# MSS_MCRC register map
Vendor: Texas Instruments
Peripheral module from a debugger description file (folder awr2x44p).
Registers are 32-bit, read-only, no defined reset value unless marked. A register's access mark holds for its fields unless they carry their own. Offsets are as the file gives them; lines under a group give offsets from that group; [hi:lo] are bit positions; {n}, {i} and the like mark numbered series; 'fields as' and 'values as' point back to an identical list; <NAME> marks a mode.

## MSS_MCRC
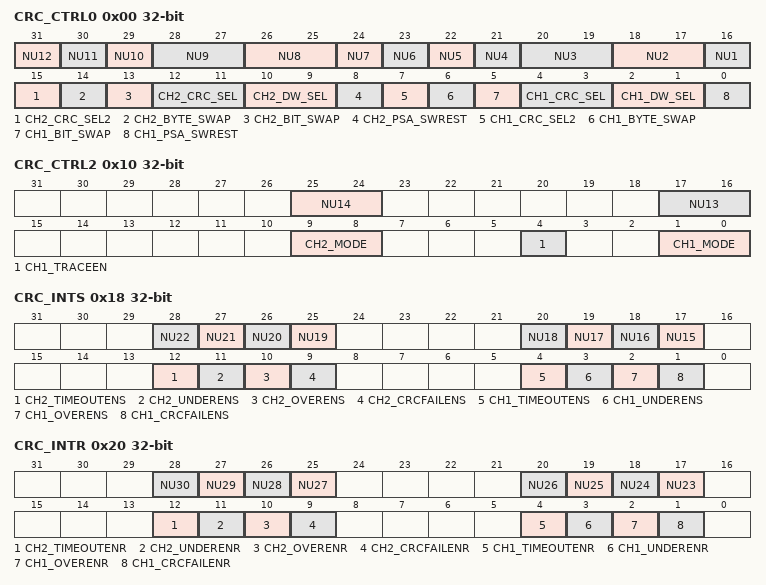
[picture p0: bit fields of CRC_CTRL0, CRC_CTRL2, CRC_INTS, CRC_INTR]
0x00 CRC_CTRL0 access per field — Contains sw reset control bit to reset PSA
  [31] NU12 ro — Reserved
  [30] NU11 ro — Reserved
  [29] NU10 ro — Reserved
  [28:27] NU9 ro — Reserved
  [26:25] NU8 ro — Reserved
  [n+17] NU{n} ro (n=4..7) — Reserved
  [20:19] NU3 ro — Reserved
  [18:17] NU2 ro — Reserved
  [16] NU1 ro — Reserved
  [15] CH2_CRC_SEL2 rw — Refer "CH2_DW_SEL" field description
  [14] CH2_BYTE_SWAP rw — BYTE SWAP Enable across Data Size 0 – Byte Swap Disabled 1 – Byte Swap enabled.
  [13] CH2_BIT_SWAP rw — msb/lsb SWAPPING 0 – msb (most significant bit First) 1 – lsb (least significant bit First)
  [12:11] CH2_CRC_SEL rw — CRC type select. {CH2_CRC_SEL2,CH2_CRC_SEL[1:0]} 000 – CRC-64 001 - CRC-16 010 – CRC-32 100 - VDA CAN, SAE-J1850 CRC-8 101 - H2F, Autosar 4.0 110 - CASTAGNOLI, iSCSI 011 - CRC64-ECMA 111 - E2E Profile 4
  [10:9] CH2_DW_SEL rw — CRC Data Size select. 000 – 64 bit Data Size 001 - 16 bit Data Size 010 – 32 Bit Data Size
  [8] CH2_PSA_SWREST rw — Channel 2 PSA Software Reset. When set, the PSA Signature Register is reset to all zero. Software reset does not reset software reset bit itself. Therefore, CPU is required to clear this bit by writing a ‘0’. 0 = PSA Signature Register not reset 1 = PSA Signature Register reset
  [7] CH1_CRC_SEL2 rw — Refer "CH1_DW_SEL" field description
  [6] CH1_BYTE_SWAP rw — BYTE SWAP Enable across Data Size 0 – Byte Swap Disabled 1 – Byte Swap enabled.
  [5] CH1_BIT_SWAP rw — msb/lsb SWAPPING 0 – msb (most significant bit First) 1 – lsb (least significant bit First)
  [4:3] CH1_CRC_SEL rw — CRC type select. {CH1_CRC_SEL2,CH1_CRC_SEL[1:0]} 000 – CRC-64 001 - CRC-16 010 – CRC-32 100 - VDA CAN, SAE-J1850 CRC-8 101 - H2F, Autosar 4.0 110 - CASTAGNOLI, iSCSI 011 - CRC64-ECMA 111 - E2E Profile 4
  [2:1] CH1_DW_SEL rw — CRC Data Size select. 000 – 64 bit Data Size 001 - 16 bit Data Size 010 – 32 Bit Data Size
  [0] CH1_PSA_SWREST rw — Channel 1 PSA Software Reset. When set, the PSA Signature Register is reset to all zero. Software reset does not reset software reset bit itself. Therefore, CPU is required to clear this bit by writing a ‘0’. 0 = PSA Signature Register not reset 1 = PSA Signature Register reset
0x08 CRC_CTRL1 access per field — Contains power down control bit
  [0] PWDN rw — Power Down. When set, MCRC moduleMCRC Module is put in power down mode. 0 = MCRC is not in power down mode 1 = MCRC is in power down mode
0x10 CRC_CTRL2 access per field — Contains channel mode, data trace enable control bits
  [25:24] NU14 ro — Reserved
  [17:16] NU13 ro — Reserved
  [9:8] CH2_MODE rw — Channel 2 Mode: 0 0 = Data Capture mode. In this mode, the PSA Signature Register does not compress data when it is written. Any data written to PSA Signature Register is simply captured by PSA Signature Register without any compression. This mode can be used to plant seed value into the PSA register 0 1 = AUTO mode 1 0 = reserved 1 1 = Full-CPU mode
  [4] CH1_TRACEEN rw — Channel 1 Data Trace Enable. When set, the channel is put into data trace mode. The channel snoops on the CPU VBUSM, ITCM, DTCM buses for any read transaction. Any read data on these buses is compressed by the PSA Signature Register. When suspend is on, the PSA Signature Register does not compress any read data on these buses. 0 = Data Trace disable 1 = Data Trace enable
  [1:0] CH1_MODE rw — Channel 1 Mode: 0 0 = Data Capture mode. In this mode, the PSA Signature Register does not compress data when it is written. Any data written to PSA Signature Register is simply captured by PSA Signature Register without any compression. This mode can be used to plant seed value into the PSA register 0 1 = AUTO mode 1 0 = reserved 1 1 = Full-CPU mode
0x18 CRC_INTS access per field — Write one to a bit to enable a interrupt
  [n+6] NU{n} ro (n=19..22) — Reserved
  [n+2] NU{n} ro (n=15..18) — Reserved
  [12] CH2_TIMEOUTENS rw — Channel 2 Timeout Interrupt Enable Bit. Writing a one to this bit enable the timeout interrupt. Writing a zero has no effect. Reading from this bit gives the status (interrupt enable/disable). User and privileged mode read: 0 = Timeout Interrupt disable 1 = Timeout Interrupt enable User and privileged mode write: 0 = Has no effect 1 = Timeout Interrupt enable
  [11] CH2_UNDERENS rw — Channel 2 Underrun Interrupt Enable Bit. Writing a one to this bit enable the underrun interrupt. Writing a zero has no effect. Reading from this bit gives the status (interrupt enable/disable). User and privileged mode read: 0 = Underrun Interrupt disable 1 = Underrun Interrupt enable User and privileged mode write: 0 = Has no effect 1 = Underrun Interrupt enable
  [10] CH2_OVERENS rw — Channel 2 Overrun Interrupt Enable Bit. Writing a one to this bit enable the overrun interrupt. Writing a zero has no effect. Reading from this bit gives the status (interrupt enable/disable). User and privileged mode read: 0 = Overrun Interrupt disable 1 = Overrun Interrupt enable User and privileged mode write: 0 = Has no effect 1 = Overrun Interrupt enable
  [9] CH2_CRCFAILENS rw — Channel 2 CRC Fail Interrupt Enable Bit. Writing a one to this bit enable the CRC fail interrupt. Writing a zero has no effect. Reading from this bit gives the status (interrupt enable/disable). User and privileged mode read: 0 = CRC Fail Interrupt disable 1 = CRC Fail Interrupt enable User and privileged mode write: 0 = Has no effect 1 = CRC Fail Interrupt enable
  [4] CH1_TIMEOUTENS rw — Channel 1 Timeout Interrupt Enable Bit. Writing a one to this bit enable the timeout interrupt. Writing a zero has no effect. Reading from this bit gives the status (interrupt enable/disable). User and privileged mode read: 0 = Timeout Interrupt disable 1 = Timeout Interrupt enable User and privileged mode write: 0 = Has no effect 1 = Timeout Interrupt enable
  [3] CH1_UNDERENS rw — Channel 1 Underrun Interrupt Enable Bit. Writing a one to this bit enable the underrun interrupt. Writing a zero has no effect. Reading from this bit gives the status (interrupt enable/disable). User and privileged mode read: 0 = Underrun Interrupt disable 1 = Underrun Interrupt enable User and privileged mode write: 0 = Has no effect 1 = Underrun Interrupt enable
  [2] CH1_OVERENS rw — Channel 1 Overrun Interrupt Enable Bit. Writing a one to this bit enable the overrun interrupt. Writing a zero has no effect. Reading from this bit gives the status (interrupt enable/disable). User and privileged mode read: 0 = Overrun Interrupt disable 1 = Overrun Interrupt enable User and privileged mode write: 0 = Has no effect 1 = Overrun Interrupt enable
  [1] CH1_CRCFAILENS rw — Channel 1 CRC Fail Interrupt Enable Bit. Writing a one to this bit enable the CRC fail interrupt. Writing a zero has no effect. Reading from this bit gives the status (interrupt enable/disable). User and privileged mode read: 0 = CRC Fail Interrupt disable 1 = CRC Fail Interrupt enable User and privileged mode write: 0 = Has no effect 1 = CRC Fail Interrupt enable
0x20 CRC_INTR access per field — Write one to a bit to disable a interrupt
  [n-2] NU{n} ro (n=27..30) — Reserved
  [n-6] NU{n} ro (n=23..26) — Reserved
  [12] CH2_TIMEOUTENR rw — Channel 2 Timeout Interrupt Disable Bit. Writing a one to this bit disable the timeout interrupt. Writing a zero has no effect. Reading from this bit gives the status (interrupt enable/disable). User and privileged mode read: 0 = Timeout Interrupt disable 1 = Timeout Interrupt enable User and privileged mode write: 0 = Has no effect 1 = Timeout Interrupt disable
  [11] CH2_UNDERENR rw — Channel 2 Underrun Interrupt Disable Bit. Writing a one to this bit disable the underrun interrupt. Writing a zero has no effect. Reading from this bit gives the status (interrupt enable/dis- able). User and privileged mode read: 0 = Underrun Interrupt disable 1 = Underrun Interrupt enable User and privileged mode write: 0 = Has no effect 1 = Underrun Interrupt disable
  [10] CH2_OVERENR rw — Channel 2 Overrun Interrupt Disable Bit. Writing a one to this bit disable the overrun interrupt. Writing a zero has no effect. Reading from this bit gives the status (interrupt enable/disable). User and privileged mode read: 0 = Overrun Interrupt disable 1 = Overrun Interrupt enable User and privileged mode write: 0 = Has no effect 1 = Overrun Interrupt disable
  [9] CH2_CRCFAILENR rw — Channel 2 CRC Fail Interrupt Disable Bit. Writing a one to this bit disable the CRC fail interrupt. Writing a zero has no effect. Reading from this bit gives the status (interrupt enable/disable). User and privileged mode read: 0 = CRC Fail Interrupt disable 1 = CRC Fail Interrupt enable User and privileged mode write: 0 = Has no effect 1 = CRC Fail Interrupt disable
  [4] CH1_TIMEOUTENR rw — Channel 1 Timeout Interrupt Disable Bit. Writing a one to this bit disable the timeout interrupt. Writing a zero has no effect. Reading from this bit gives the status (interrupt enable/disable). User and privileged mode read: 0 = Timeout Interrupt disable 1 = Timeout Interrupt enable User and privileged mode write: 0 = Has no effect 1 = Timeout Interrupt disable
  [3] CH1_UNDERENR rw — Channel 1 Underrun Interrupt Disable Bit. Writing a one to this bit disable the underrun interrupt. Writing a zero has no effect. Reading from this bit gives the status (interrupt enable/dis- able). User and privileged mode read: 0 = Underrun Interrupt disable 1 = Underrun Interrupt enable User and privileged mode write: 0 = Has no effect 1 = Underrun Interrupt disable
  [2] CH1_OVERENR rw — Channel 1 Overrun Interrupt Disable Bit. Writing a one to this bit disable the overrun interrupt. Writing a zero has no effect. Reading from this bit gives the status (interrupt enable/disable). User and privileged mode read: 0 = Overrun Interrupt disable 1 = Overrun Interrupt enable User and privileged mode write: 0 = Has no effect 1 = Overrun Interrupt disable
  [1] CH1_CRCFAILENR rw — Channel 1 CRC Fail Interrupt Disable Bit. Writing a one to this bit disable the CRC fail interrupt. Writing a zero has no effect. Reading from this bit gives the status (interrupt enable/disable). User and privileged mode read: 0 = CRC Fail Interrupt disable 1 = CRC Fail Interrupt enable User and privileged mode write: 0 = Has no effect 1 = CRC Fail Interrupt disable
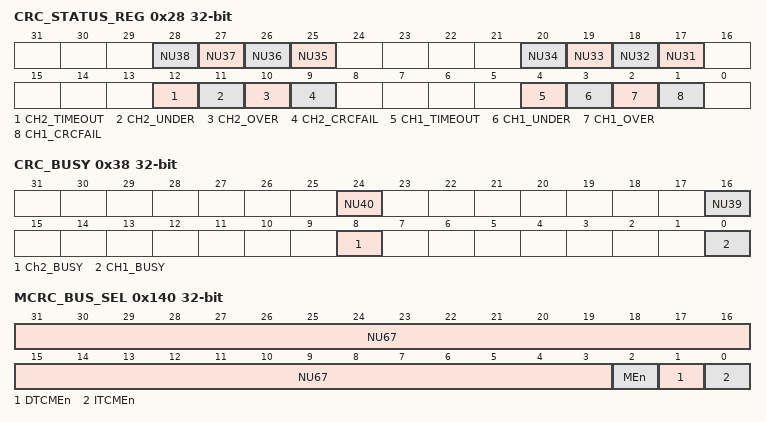
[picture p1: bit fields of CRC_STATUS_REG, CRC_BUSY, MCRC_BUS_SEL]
0x28 CRC_STATUS_REG access per field — Contains interrupt flags for different types of interrupt
  [n-10] NU{n} ro (n=35..38) — Reserved
  [n-14] NU{n} ro (n=31..34) — Reserved
  [12] CH2_TIMEOUT rw — Channel 2 CRC Timeout Status Flag. This bit is cleared by writing a ’1’ to it only. Writing ’0’ has no effect. This bit is set in AUTO mode. 0 = No timeout interrupt is active 1 = Timeout interrupt is active
  [11] CH2_UNDER rw — Channel 2 CRC Underrun Status Flag. This bit is cleared by writing a ’1’ to it only. Writing ’0’ has no effect. This bit is set in AUTO mode only 0 = No underrun interrupt is active 1 = Underrun interrupt is active
  [10] CH2_OVER rw — Channel 2 CRC Overrun Status Flag. This bit is cleared by writing a ’1’ to it only. Writing ’0’ has no effect. This bit is set in AUTO mode 0 = No overrun interrupt is active 1 = Overrun interrupt is active
  [9] CH2_CRCFAIL rw — Channel 2 CRC Compare Fail Status Flag. This bit is cleared by writing a ’1’ to it only. Writing ’0’ has no effect. This bit is set in AUTO mode only. 0 = No CRC compare fail interrupt is active 1 = CRC compare fail interrupt is active
  [4] CH1_TIMEOUT rw — Channel 1 CRC Timeout Status Flag. This bit is cleared by writing a ’1’ to it only. Writing ’0’ has no effect. This bit is set in AUTO mode. 0 = No timeout interrupt is active 1 = Timeout interrupt is active
  [3] CH1_UNDER rw — Channel 1 CRC Underrun Status Flag. This bit is cleared by writing a ’1’ to it only. Writing ’0’ has no effect. This bit is set in AUTO mode only 0 = No underrun interrupt is active 1 = Underrun interrupt is active
  [2] CH1_OVER rw — Channel 1 CRC Overrun Status Flag. This bit is cleared by writing a ’1’ to it only. Writing ’0’ has no effect. This bit is set in AUTO mode 0 = No overrun interrupt is active 1 = Overrun interrupt is active
  [1] CH1_CRCFAIL rw — Channel 1 CRC Compare Fail Status Flag. This bit is cleared by writing a ’1’ to it only. Writing ’0’ has no effect. This bit is set in AUTO mode only. 0 = No CRC compare fail interrupt is active 1 = CRC compare fail interrupt is active
0x30 CRC_INT_OFFSET_REG access per field — Contains the interrupt offset vector address
  [7:0] OFSTREG rw — CRC Interrupt Offset. This register indicates the highest priority pending interrupt vector address. Reading the offset register auto- matically clear the respective interrupt flag. Please reference Table 1–3. for details.
0x38 CRC_BUSY — Contains the busy flag for each channel
  [24] NU40 — Reserved
  [16] NU39 — Reserved
  [8] Ch2_BUSY — Ch2_BUSY. During AUTO mode, the busy flag is set when the first data pattern of the block is compressed and remains set until the the last data pattern of the block is compressed. The flag is cleared when the last data pattern of the block is compressed.
  [0] CH1_BUSY — CH1_BUSY. During AUTO mode, the busy flag is set when the first data pattern of the block is compressed and remains set until the the last data pattern of the block is compressed. The flag is cleared when the last data pattern of the block is compressed.
0x40 CRC_PCOUNT_REG1 access per field — Channel 1 preload register for the pattern count
  [19:0] CRC_PAT_COUNT1 rw — Channel 1 Pattern Counter Preload Register. This register con- tains the number of data patterns in one sector to be compressed before a CRC is performed.
0x44 CRC_SCOUNT_REG1 access per field — Channel 1 preload register for the sector count
  [15:0] CRC_SEC_COUNT1 rw — Channel 1 Sector Counter Preload Register. This register con- tains the number of sectors in one block of memory.
0x48 CRC_CURSEC_REG1 access per field — Channel 1 current sector register contains the sector number which causes CRC failure
  [15:0] CRC_CURSEC1 rw — Channel 1 Current Sector ID Register. In AUTO mode, this register contains the current sector number of which the signature verification fails. The sector counter is a free running up counter. When a sector fails, the erroneous sector number is logged into current sector ID register and the CRC fail interrupt is generated The sector ID register is frozen until it is read and the CRC fail status bit is cleared by CPU. While it is frozen, it does not capture another erroneous sector number. When this condition happens, an overrun interrupt is generated instead. Once the register is read and the CRC fail interrupt flag is cleared it can capture new erro- neous sector number.
0x4C CRC_WDTOPLD1 access per field — Channel 1 timeout pre-load value to check if within a given time DMA initiates a block transfer
  [23:0] CRC_WDTOPLD1 rw — Channel 1 Watchdog Timeout Counter Preload Register. This register contains the number of clock cycles within which the DMA must transfer the next block of data patterns.
0x50 CRC_BCTOPLD1 access per field — Channel 1 timeout pre-load value to check if one block of patterns are compressed with a given time
  [23:0] CRC_BCTOPLD1 rw — Channel 1 Block Complete Timeout Counter Preload Regis- ter. This register contains the number of clock cycles within which the CRC for an entire block needs to complete before a timeout interrupt is generated.
0x60 PSA_SIGREGL1 rw — Channel 1 PSA signature low register
  [31:0] PSASIG1_31_0 — Channel 1 PSA Signature Low Register. This register contains the value stored at PSASIG1[31:0] register.
0x64 PSA_SIGREGH1 rw — Channel 1 PSA signature high register
  [31:0] PSA_SIG1_63_32 — Channel 1 PSA Signature High Register. This register contains the value stored at PSASIG1[63:32] register.
0x68 CRC_REGL1 rw — Channel 1 CRC value low register
  [31:0] CRC1_31_0 — Channel 1 CRC Value Low Register. This register contains the current known good signature value stored at CRC1[31:0] regis- ter.
0x6C CRC_REGH1 rw — Channel 1 CRC value high register
  [31:0] CRC1_63_32 — Channel 1 CRC Value High Register. This register contains the current known good signature value stored at CRC1[63:32] regis- ter.
0x70 PSA_SECSIGREGL1 — Channel 1 PSA sector signature low regis-ter
  [31:0] PSASECSIG1_31_0 — Channel 1 PSA Sector Signature Low Register. This register contains the value stored at PSASECSIG1[31:0] register.
0x74 PSA_SECSIGREGH1 — Channel 1 PSA sector signature high regis-ter
  [31:0] PSASECSIG1_63_32 — Channel 1 PSA Sector Signature High Register. This register contains the value stored at PSASECSIG1[63:32] register.
0x78 RAW_DATAREGL1 — Channel 1 un-compressed raw data low register
  [31:0] RAW_DATA1_31_0 — Channel 1 Raw Data Low Register. This register contains bit 31:0 of the un-compressed raw data.
0x7C RAW_DATAREGH1 — Channel 1 un-compressed raw data high register
  [31:0] RAW_DATA1_63_32 — Channel 1 Raw Data High Register. This register contains bit 63:32 of the un-compressed raw data.
0x80 CRC_PCOUNT_REG2 access per field — Channel 2 preload register for the pattern count
  [19:0] CRC_PAT_COUNT2 rw — Channel 2 Pattern Counter Preload Register. This register con- tains the number of data patterns in one sector to be compressed before a CRC is performed.
0x84 CRC_SCOUNT_REG2 access per field — Channel 2 preload register for the sector count
  [15:0] CRC_SEC_COUNT2 rw — Channel 2 Sector Counter Preload Register. This register con- tains the number of sectors in one block of memory.
0x88 CRC_CURSEC_REG2 access per field — Channel 2 current sector register contains the sector number which causes CRC fail-ure
  [15:0] CRC_CURSEC2 rw — Channel 2 Current Sector ID Register. In AUTO mode, this register contains the current sector number of which the signature verification fails. The sector counter is a free running up counter. When a sector fails, the erroneous sector number is logged into current sector ID register and the CRC fail interrupt is generated The sector ID register is frozen until it is read and the CRC fail status bit is cleared by CPU. While it is frozen, it does not capture another erroneous sector number. When this condition happens, an overrun interrupt is generated instead. Once the register is read and the CRC fail interrupt flag is cleared it can capture new erro- neous sector number.
0x8C CRC_WDTOPLD2 access per field — Channel 2 timeout pre-load value to check if within a given time DMA initiates a block transfer
  [23:0] CRC_WDTOPLD2 rw — Channel 2 Watchdog Timeout Counter Preload Register. This register contains the number of clock cycles within which the DMA must transfer the next block of data patterns.
0x90 CRC_BCTOPLD2 access per field — Channel 2 timeout pre-load value to check if one block of patterns are compressed with a given time
  [23:0] CRC_BCTOPLD2 rw — Channel 2 Block Complete Timeout Counter Preload Regis- ter. This register contains the number of clock cycles within which the CRC for an entire block needs to complete before a timeout interrupt is generated.
0xA0 PSA_SIGREGL2 rw — Channel 2 PSA signature low register
  [31:0] PSASIG2_31_0 — Channel 2 PSA Signature Low Register. This register contains the value stored at PSASIG2[31:0] register.
0xA4 PSA_SIGREGH2 rw — Channel 2 PSA signature high register
  [31:0] PSA_SIG2_63_32 — Channel 2 PSA Signature High Register. This register contains the value stored at PSASIG2[63:32] register.
0xA8 CRC_REGL2 rw — Channel 2 CRC value low register
  [31:0] CRC2_31_0 — Channel 2 CRC Value Low Register. This register contains the current known good signature value stored at CRC2[31:0] regis- ter.
0xAC CRC_REGH2 rw — Channel 2 CRC value high register
  [31:0] CRC2_63_32 — Channel 2 CRC Value High Register. This register contains the current known good signature value stored at CRC2[63:32] regis- ter.
0xB0 PSA_SECSIGREGL2 — Channel 2 PSA sector signature low regis-ter
  [31:0] PSASECSIG2_31_0 — Channel 2 PSA Sector Signature Low Register. This register contains the value stored at PSASECSIG2[31:0] register.
0xB4 PSA_SECSIGREGH2 — Channel 2 PSA sector signature high regis-ter
  [31:0] PSASECSIG2_63_32 — Channel 2 PSA Sector Signature High Register. This register contains the value stored at PSASECSIG2[63:32] register.
0xB8 RAW_DATAREGL2 — Channel 2 un-compressed raw data low register
  [31:0] RAW_DATA2_31_0 — Channel 2 Raw Data Low Register. This register contains bit 31:0 of the un-compressed raw data.
0xBC RAW_DATAREGH2 — Channel 2 un-compressed raw data high Register
  [31:0] RAW_DATA2_63_32 — Channel 2 Raw Data High Register. This register contains bit 63:32 of the un-compressed raw data.
0xC0 CRC_PCOUNT_REG3 — Channel 3 preload register for the pattern count
  [19:0] NU41 — Reserved
0xC4 CRC_SCOUNT_REG3 — Channel 3 preload register for the sector count
  [15:0] NU42 — Reserved
0xC8 CRC_CURSEC_REG3 — Channel 3 current sector register contains the sector number which causes CRC fail-ure
  [15:0] NU43 — Reserved
0xCC CRC_WDTOPLD3 — Channel 3 timeout pre-load value to check if within a given time DMA initiates a block transfer
  [23:0] NU44 — Reserved
0xD0 CRC_BCTOPLD3 — Channel 3 timeout pre-load value to check if one block of patterns are compressed with a given time
  [23:0] NU45 — Reserved
0xE0 PSA_SIGREGL3 — Channel 3 PSA signature low register
  [31:0] NU46 — Reserved
0xE4 PSA_SIGREGH3 — Channel 3 PSA signature high register
  [31:0] NU47 — Reserved
0xE8 CRC_REGL3 — Channel 3 CRC value low register
  [31:0] NU48 — Reserved
0xEC CRC_REGH3 — Channel 3 CRC value high register
  [31:0] NU49 — Reserved
0xF0 PSA_SECSIGREGL3 — Channel 3 PSA sector signature low regis-ter
  [31:0] NU50 — Reserved
0xF4 PSA_SECSIGREGH3 — Channel 3 PSA sector signature high regis-ter
  [31:0] NU51 — Reserved
0xF8 RAW_DATAREGL3 — Channel 3 un-compressed raw data low register
  [31:0] NU52 — Reserved
0xFC RAW_DATAREGH3 — Channel 3 un-compressed raw data high Register
  [31:0] NU53 — Reserved
0x100 CRC_PCOUNT_REG4 — Channel 4 preload register for the pattern count
  [19:0] NU54 — Reserved
0x104 CRC_SCOUNT_REG4 — Channel 4 preload register for the sector count
  [15:0] NU55 — Reserved
0x108 CRC_CURSEC_REG4 — Channel 4 current sector register contains the sector number which causes CRC fail-ure
  [15:0] NU56 — Reserved
0x10C CRC_WDTOPLD4 — Channel 4 timeout pre-load value to check if within a given time DMA initiates a block transfer
  [23:0] NU57 — Reserved
0x110 CRC_BCTOPLD4 — Channel 4 timeout pre-load value to check if one block of patterns are compressed with a given time
  [23:0] NU58 — Reserved
0x120 PSA_SIGREGL4 — Channel 4 PSA signature low register
  [31:0] NU59 — Reserved
0x124 PSA_SIGREGH4 — Channel 4 PSA signature high register
  [31:0] NU60 — Reserved
0x128 CRC_REGL4 — Channel 4 CRC value low register
  [31:0] NU61 — Reserved
0x12C CRC_REGH4 — Channel 4 CRC value high register
  [31:0] NU62 — Reserved
0x130 PSA_SECSIGREGL4 — Channel 4 PSA sector signature low regis-ter
  [31:0] NU63 — Reserved
0x134 PSA_SECSIGREGH4 — Channel 4 PSA sector signature high regis-ter
  [31:0] NU64 — Reserved
0x138 RAW_DATAREGL4 — Channel 4 un-compressed raw data low register
  [31:0] NU65 — Reserved
0x13C RAW_DATAREGH4 — Channel 4 un-compressed raw data high Register
  [31:0] NU66 — Reserved
0x140 MCRC_BUS_SEL access per field — Disables either or all tracing of data buses
  [31:3] NU67 ro — Reserved
  [2] MEn rw — MEn. Enable/disables the tracing of VBUSM 0: Tracing of VBUSM master bus has been disabled 1: Tracing of VBUSM master bus has been enabled
  [1] DTCMEn rw — DTCMEn. Enable/disables the tracing of data TCM 0: Tracing of DTCM_ODD and DTCM_EVEN buses have been disabled 1: Tracing of DTCM_ODD and DTCM_EVEN buses have been enabled
  [0] ITCMEn rw — ITCMEn. Enable/disables the tracing of instruction TCM 0: Tracing of ITCM bus has been disabled 1: Tracing of ITCM bus has been enabled
0x144 MCRC_RESERVED — 0x144 to 0x1FF is reserved area.
  [31:0] NU68
